# ioADuCM302x register map
Registers are 16-bit, access not given, no defined reset value unless marked. A register's access mark holds for its fields unless they carry their own. Addresses are absolute; registers are grouped by the start of their names; [hi:lo] are bit positions; {n}, {i} and the like mark numbered series.

## GPIO0
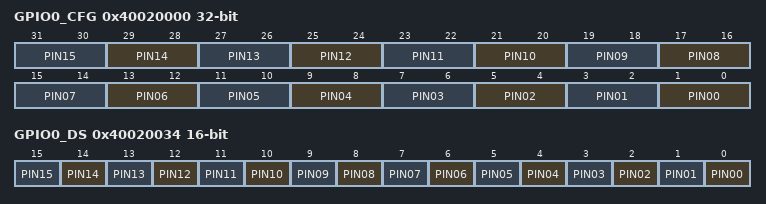
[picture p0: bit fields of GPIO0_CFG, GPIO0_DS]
0x40020000 GPIO0_CFG 32-bit
  [2n+1:2n] PIN{n:02} (n=0..15)
0x40020004 GPIO0_OEN
0x40020008 GPIO0_PE
0x4002000C GPIO0_IEN
0x40020010 GPIO0_IN
0x40020014 GPIO0_OUT
0x40020018 GPIO0_SET
0x4002001C GPIO0_CLR
0x40020020 GPIO0_TGL
0x40020024 GPIO0_POL
0x40020028 GPIO0_IENA
0x4002002C GPIO0_IENB
0x40020030 GPIO0_INT
0x40020034 GPIO0_DS
  [n] PIN{n:02} (n=0..15)

## GPIO1
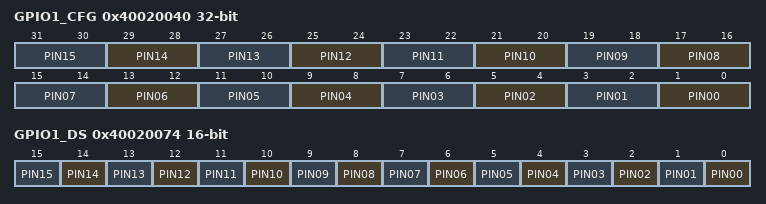
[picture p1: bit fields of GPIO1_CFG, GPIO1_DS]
0x40020040 GPIO1_CFG 32-bit
  [2n+1:2n] PIN{n:02} (n=0..15)
0x40020044 GPIO1_OEN
0x40020048 GPIO1_PE
0x4002004C GPIO1_IEN
0x40020050 GPIO1_IN
0x40020054 GPIO1_OUT
0x40020058 GPIO1_SET
0x4002005C GPIO1_CLR
0x40020060 GPIO1_TGL
0x40020064 GPIO1_POL
0x40020068 GPIO1_IENA
0x4002006C GPIO1_IENB
0x40020070 GPIO1_INT
0x40020074 GPIO1_DS
  [n] PIN{n:02} (n=0..15)

## GPIO2
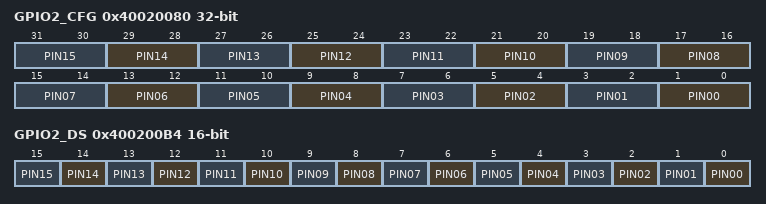
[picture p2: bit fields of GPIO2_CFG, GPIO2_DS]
0x40020080 GPIO2_CFG 32-bit
  [2n+1:2n] PIN{n:02} (n=0..15)
0x40020084 GPIO2_OEN
0x40020088 GPIO2_PE
0x4002008C GPIO2_IEN
0x40020090 GPIO2_IN
0x40020094 GPIO2_OUT
0x40020098 GPIO2_SET
0x4002009C GPIO2_CLR
0x400200A0 GPIO2_TGL
0x400200A4 GPIO2_POL
0x400200A8 GPIO2_IENA
0x400200AC GPIO2_IENB
0x400200B0 GPIO2_INT
0x400200B4 GPIO2_DS
  [n] PIN{n:02} (n=0..15)

## SPORT0
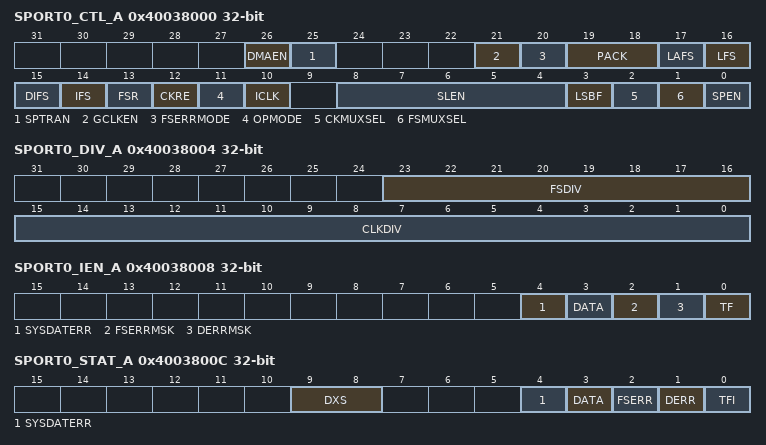
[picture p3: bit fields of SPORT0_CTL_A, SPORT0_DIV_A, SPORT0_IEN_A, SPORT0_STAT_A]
0x40038000 SPORT0_CTL_A 32-bit
  [26] DMAEN, [25] SPTRAN, [21] GCLKEN, [20] FSERRMODE, [19:18] PACK, [17] LAFS, [16] LFS, [15] DIFS, [14] IFS, [13] FSR, [12] CKRE, [11] OPMODE, [10] ICLK, [8:4] SLEN, [3] LSBF, [2] CKMUXSEL, [1] FSMUXSEL, [0] SPEN
0x40038004 SPORT0_DIV_A 32-bit
  [23:16] FSDIV, [15:0] CLKDIV
0x40038008 SPORT0_IEN_A 32-bit
  [4] SYSDATERR, [3] DATA, [2] FSERRMSK, [1] DERRMSK, [0] TF
0x4003800C SPORT0_STAT_A 32-bit
  [9:8] DXS, [4] SYSDATERR, [3] DATA, [2] FSERR, [1] DERR, [0] TFI
0x40038010 SPORT0_NUMTRAN_A 32-bit
  [11:0] VALUE
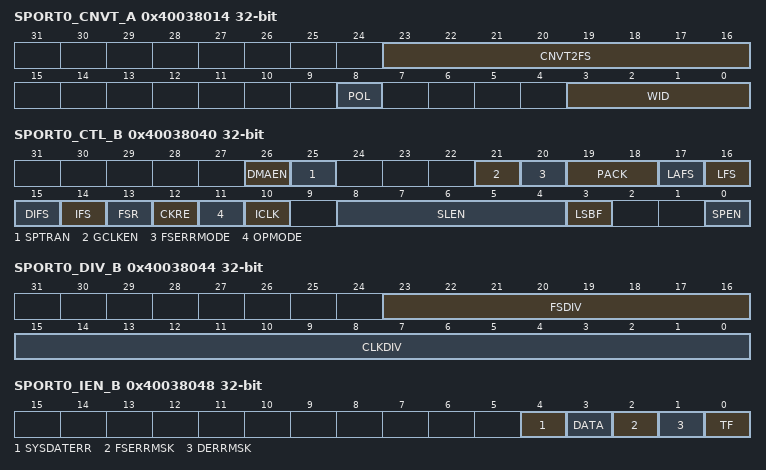
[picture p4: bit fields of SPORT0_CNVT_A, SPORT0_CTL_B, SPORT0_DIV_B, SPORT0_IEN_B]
0x40038014 SPORT0_CNVT_A 32-bit
  [23:16] CNVT2FS, [8] POL, [3:0] WID
0x40038020 SPORT0_TX_A 32-bit
0x40038028 SPORT0_RX_A 32-bit
0x40038040 SPORT0_CTL_B 32-bit
  [26] DMAEN, [25] SPTRAN, [21] GCLKEN, [20] FSERRMODE, [19:18] PACK, [17] LAFS, [16] LFS, [15] DIFS, [14] IFS, [13] FSR, [12] CKRE, [11] OPMODE, [10] ICLK, [8:4] SLEN, [3] LSBF, [0] SPEN
0x40038044 SPORT0_DIV_B 32-bit
  [23:16] FSDIV, [15:0] CLKDIV
0x40038048 SPORT0_IEN_B 32-bit
  [4] SYSDATERR, [3] DATA, [2] FSERRMSK, [1] DERRMSK, [0] TF
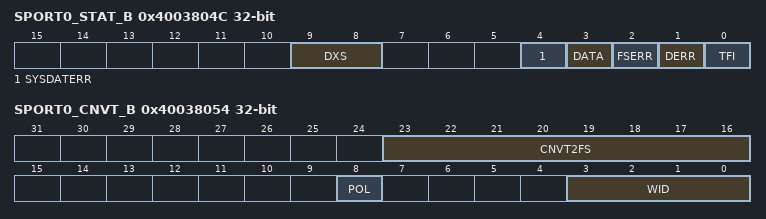
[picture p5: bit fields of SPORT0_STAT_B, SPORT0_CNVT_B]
0x4003804C SPORT0_STAT_B 32-bit
  [9:8] DXS, [4] SYSDATERR, [3] DATA, [2] FSERR, [1] DERR, [0] TFI
0x40038050 SPORT0_NUMTRAN_B 32-bit
  [11:0] VALUE
0x40038054 SPORT0_CNVT_B 32-bit
  [23:16] CNVT2FS, [8] POL, [3:0] WID
0x40038060 SPORT0_TX_B 32-bit
0x40038068 SPORT0_RX_B 32-bit

## CRC0
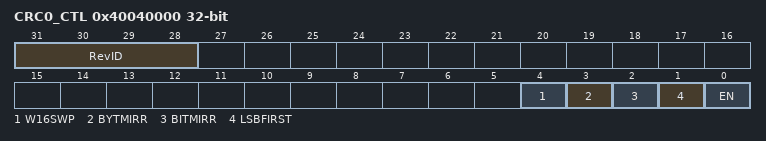
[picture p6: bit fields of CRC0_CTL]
0x40040000 CRC0_CTL 32-bit
  [31:28] RevID, [4] W16SWP, [3] BYTMIRR, [2] BITMIRR, [1] LSBFIRST, [0] EN
0x40040004 CRC0_IPDATA 32-bit
0x40040008 CRC0_RESULT 32-bit
0x4004000C CRC0_POLY 32-bit
{0x40040010+i} CRC0_IPBITS{i} 8-bit (i=0..7)
0x40040010 CRC0_IPBYTE 8-bit

## RNG0
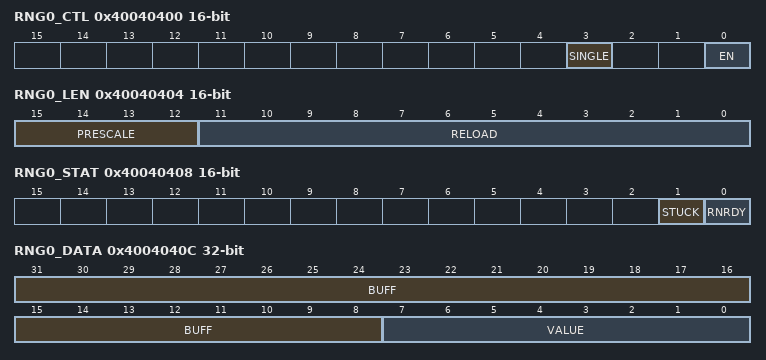
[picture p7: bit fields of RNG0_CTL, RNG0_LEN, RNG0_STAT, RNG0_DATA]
0x40040400 RNG0_CTL
  [3] SINGLE, [0] EN
0x40040404 RNG0_LEN
  [15:12] PRESCALE, [11:0] RELOAD
0x40040408 RNG0_STAT
  [1] STUCK, [0] RNRDY
0x4004040C RNG0_DATA 32-bit
  [31:8] BUFF, [7:0] VALUE
0x40040410 RNG0_OSCCNT 32-bit
  [27:0] VALUE
{0x40040414+i} RNG0_OSCDIFF{i} 8-bit (i=0..3)

## CRYPT0
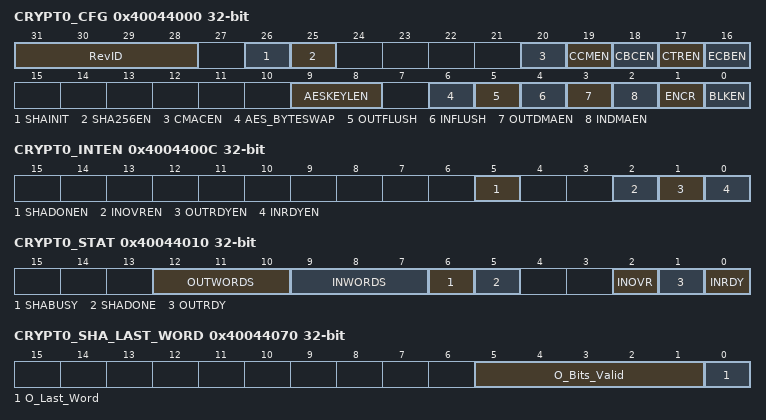
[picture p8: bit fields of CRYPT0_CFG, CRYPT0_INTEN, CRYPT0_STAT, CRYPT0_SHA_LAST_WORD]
0x40044000 CRYPT0_CFG 32-bit
  [31:28] RevID, [26] SHAINIT, [25] SHA256EN, [20] CMACEN, [19] CCMEN, [18] CBCEN, [17] CTREN, [16] ECBEN, [9:8] AESKEYLEN, [6] AES_BYTESWAP, [5] OUTFLUSH, [4] INFLUSH, [3] OUTDMAEN, [2] INDMAEN, [1] ENCR, [0] BLKEN
0x40044004 CRYPT0_DATALEN 32-bit
  [19:0] VALUE
0x40044008 CRYPT0_PREFIXLEN 32-bit
  [15:0] VALUE
0x4004400C CRYPT0_INTEN 32-bit
  [5] SHADONEN, [2] INOVREN, [1] OUTRDYEN, [0] INRDYEN
0x40044010 CRYPT0_STAT 32-bit
  [12:10] OUTWORDS, [9:7] INWORDS, [6] SHABUSY, [5] SHADONE, [2] INOVR, [1] OUTRDY, [0] INRDY
0x40044014 CRYPT0_INBUF 32-bit
0x40044018 CRYPT0_OUTBUF 32-bit
{0x4004401C+4i} CRYPT0_NONCE{i} 32-bit (i=0..3)
{0x4004402C+4i} CRYPT0_AESKEY{i} 32-bit (i=0..7)
0x4004404C CRYPT0_CNTRINIT 32-bit
  [19:0] VALUE
{0x40044050+4i} CRYPT0_SHAH{i} 32-bit (i=0..7)
0x40044070 CRYPT0_SHA_LAST_WORD 32-bit
  [5:1] O_Bits_Valid, [0] O_Last_Word
0x40044074 CRYPT0_CCM_NUM_VALID_BYTES 32-bit
  [3:0] NUM_VALID_BYTES
